# PIC32CM2532JH00064 device description
Architecture: CORTEX-M0PLUS; Family: PIC32CM; Series: PIC32CMJH00
Registers are 32-bit, read-write, reset 0x0 unless marked. A register's access mark holds for its fields unless they carry their own. Offsets are from the block's base; [hi:lo] are bit positions; {n}, {i} and the like mark numbered series.

## FREQM — Frequency Meter
Instances: FREQM 0x40002C00
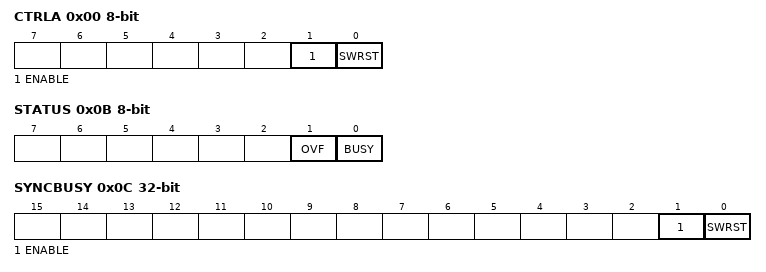
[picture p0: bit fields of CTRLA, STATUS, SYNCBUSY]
0x00 CTRLA 8-bit (WSYNC) — Control A Register
  [1] ENABLE
  [0] SWRST — Software Reset
0x01 CTRLB 8-bit wo — Control B Register
  [0] START — Start Measurement
0x02 CFGA 16-bit — Config A register
  [7:0] REFNUM — Number of Reference Clock Cycles
0x08 INTENCLR 8-bit (atomic clear) — Interrupt Enable Clear Register
  [0] DONE — Measurement Done Interrupt Enable
0x09 INTENSET 8-bit (atomic set) — Interrupt Enable Set Register
  [0] DONE — Measurement Done Interrupt Enable
0x0A INTFLAG 8-bit (atomic clear) — Interrupt Flag Register
  [0] DONE — Measurement Done
0x0B STATUS 8-bit
  [1] OVF — Sticky Count Value Overflow
  [0] BUSY — FREQM Status
0x0C SYNCBUSY ro — Synchronization Busy Register
  [1] ENABLE
  [0] SWRST — Software Reset
0x10 VALUE ro — Count Value Register
  [23:0] VALUE — Measurement Value

## GCLK — Generic Clock Generator
Instances: GCLK 0x40001C00
0x00 CTRLA 8-bit (WSYNC) — Control
  [0] SWRST — Software Reset
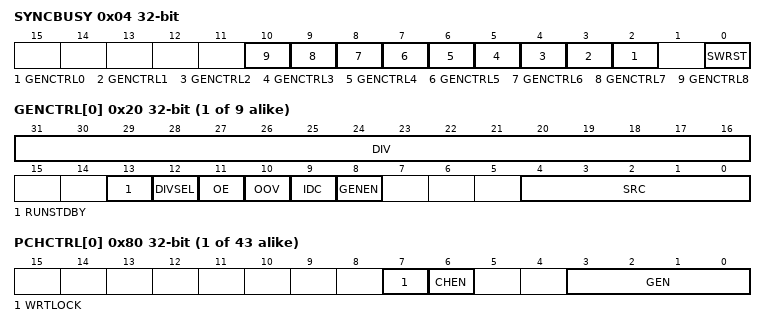
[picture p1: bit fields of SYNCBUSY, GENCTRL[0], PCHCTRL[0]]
0x04 SYNCBUSY ro — Synchronization Busy
  [n+2] GENCTRL{n} (n=0..8) — Generic Clock Generator Control {n} Synchronization Busy bit
  [0] SWRST — Software Reset Synchronization Busy bit
{0x20+4i} GENCTRL[{i}] (i=0..8) (WSYNC) — Generic Clock Generator Control
  [31:16] DIV — Division Factor
  [13] RUNSTDBY — Run in Standby
  [12] DIVSEL — Divide Selection
    0=DIV1 (Division by GENCTRLn.DIV); 1=DIV2 (Division by 2^(GENCTRLn.DIV+1))
  [11] OE — Output Enable
  [10] OOV — Output Off Value
  [9] IDC — Improve Duty Cycle
  [8] GENEN — Generic Clock Generator Enable
  [4:0] SRC — Source Select
    0=XOSC (XOSC oscillator output); 1=GCLKIN (Generator input pad (GCLK_IO)); 2=GCLKGEN1 (Generic clock generator 1 output); 3=OSCULP32K (OSCULP32K oscillator output); 4=OSC32K (OSC32K oscillator output); 5=XOSC32K (XOSC32K oscillator output); 6=OSC48M (OSC48M oscillator output); 7=FDPLL96M (FDPLL96M output)
{0x80+4i} PCHCTRL[{i}] (i=0..42) — Peripheral Clock Control
  [7] WRTLOCK — Write Lock
  [6] CHEN — Channel Enable
  [3:0] GEN — Generic Clock Generator
    {v}=GCLK{v} (Generic clock generator {v}) (v=0..8)

## ICM — Integrity Check Monitor
Instances: ICM 0x42006400
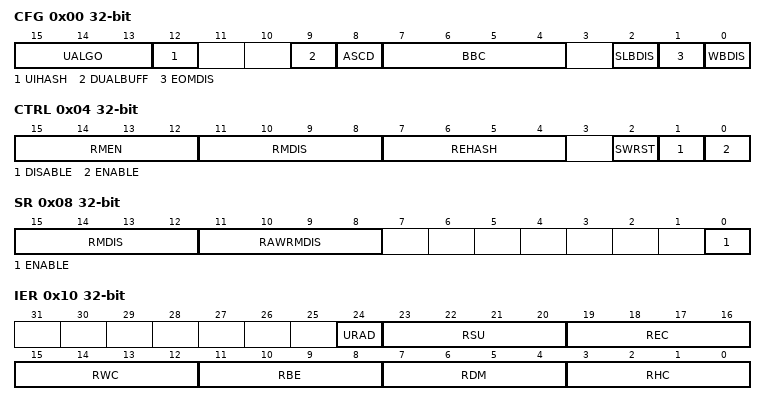
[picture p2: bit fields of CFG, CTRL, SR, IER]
0x00 CFG — Configuration
  [15:13] UALGO — User SHA Algorithm
    0=SHA1 (SHA1 Algorithm); 1=SHA256 (SHA256 Algorithm); 4=SHA224 (SHA224 Algorithm)
  [12] UIHASH — User Initial Hash Value
  [9] DUALBUFF — Dual Input Buffer
  [8] ASCD — Automatic Switch To Compare Digest
  [7:4] BBC — Bus Burden Control
  [2] SLBDIS — Secondary List Branching Disable
  [1] EOMDIS — End of Monitoring Disable
  [0] WBDIS — Write Back Disable
0x04 CTRL wo reset not defined — Control
  [15:12] RMEN — Region Monitoring Enable
  [11:8] RMDIS — Region Monitoring Disable
  [7:4] REHASH — Recompute Internal Hash
  [2] SWRST — Software Reset
  [1] DISABLE — ICM Disable Register
  [0] ENABLE — ICM Enable
0x08 SR ro — Status
  [15:12] RMDIS — Region Monitoring Disabled Status
  [11:8] RAWRMDIS — RAW Region Monitoring Disabled Status
  [0] ENABLE — ICM Controller Enable Register
0x10 IER wo (atomic set of IMR) — Interrupt Enable
  [24] URAD — Undefined Register Access Detection Interrupt Enable
  [23:20] RSU — Region Status Updated Interrupt Disable
  [19:16] REC — Region End bit Condition Detected Interrupt Enable
  [15:12] RWC — Region Wrap Condition detected Interrupt Enable
  [11:8] RBE — Region Bus Error Interrupt Enable
  [7:4] RDM — Region Digest Mismatch Interrupt Enable
  [3:0] RHC — Region Hash Completed Interrupt Enable
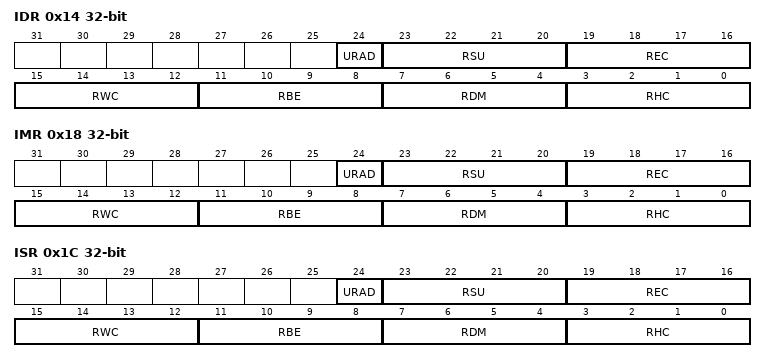
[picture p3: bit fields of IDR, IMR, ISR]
0x14 IDR wo (atomic clear of IMR) — Interrupt Disable
  [24] URAD — Undefined Register Access Detection Interrupt Disable
  [23:20] RSU — Region Status Updated Interrupt Disable
  [19:16] REC — Region End bit Condition detected Interrupt Disable
  [15:12] RWC — Region Wrap Condition Detected Interrupt Disable
  [11:8] RBE — Region Bus Error Interrupt Disable
  [7:4] RDM — Region Digest Mismatch Interrupt Disable
  [3:0] RHC — Region Hash Completed Interrupt Disable
0x18 IMR ro — Interrupt Mask
  [24] URAD — Undefined Register Access Detection Interrupt Mask
  [23:20] RSU — Region Status Updated Interrupt Mask
  [19:16] REC — Region End bit Condition Detected Interrupt Mask
  [15:12] RWC — Region Wrap Condition Detected Interrupt Mask
  [11:8] RBE — Region Bus Error Interrupt Mask
  [7:4] RDM — Region Digest Mismatch Interrupt Mask
  [3:0] RHC — Region Hash Completed Interrupt Mask
0x1C ISR ro — Interrupt Status
  [24] URAD — Undefined Register Access Detection Status
  [23:20] RSU — Region Status Updated Detected
  [19:16] REC — Region End bit Condition Detected
  [15:12] RWC — Region Wrap Condition Detected
  [11:8] RBE — Region Bus Error
  [7:4] RDM — Region Digest Mismatch
  [3:0] RHC — Region Hash Completed
0x20 UASR ro — Undefined Access Status
  [2:0] URAT — Undefined Register Access Trace
    0=UNSPEC_STRUCT_MEMBER (Unspecified structure member set to one detected when the descriptor is loaded); 1=CFG_MODIFIED (CFG modified during active monitoring); 2=DSCR_MODIFIED (DSCR modified during active monitoring); 3=HASH_MODIFIED (HASH modified during active monitoring); 4=READ_ACCESS (Write-only register read access)
0x30 DSCR — Region Descriptor Area Start Address
  [31:6] DASA — Descriptor Area Start Address
0x34 HASH — Region Hash Area Start Address
  [31:7] HASA — Hash Area Start Address
{0x38+4i} UIHVAL[{i}] (i=0..7) wo — User Initial Hash Value n
  [31:0] VAL — Initial Hash Value

## Notices in the file
Copyright (c) 2019 Microchip Technology Inc.
SPDX-License-Identifier: Apache-2.0
Licensed under the Apache License, Version 2.0 (the "License");
you may not use this file except in compliance with the License.
You may obtain a copy of the License at
http://www.apache.org/licenses/LICENSE-2.0
Unless required by applicable law or agreed to in writing, software
distributed under the License is distributed on an "AS IS" BASIS,
WITHOUT WARRANTIES OR CONDITIONS OF ANY KIND, either express or implied.
See the License for the specific language governing permissions and
limitations under the License.
